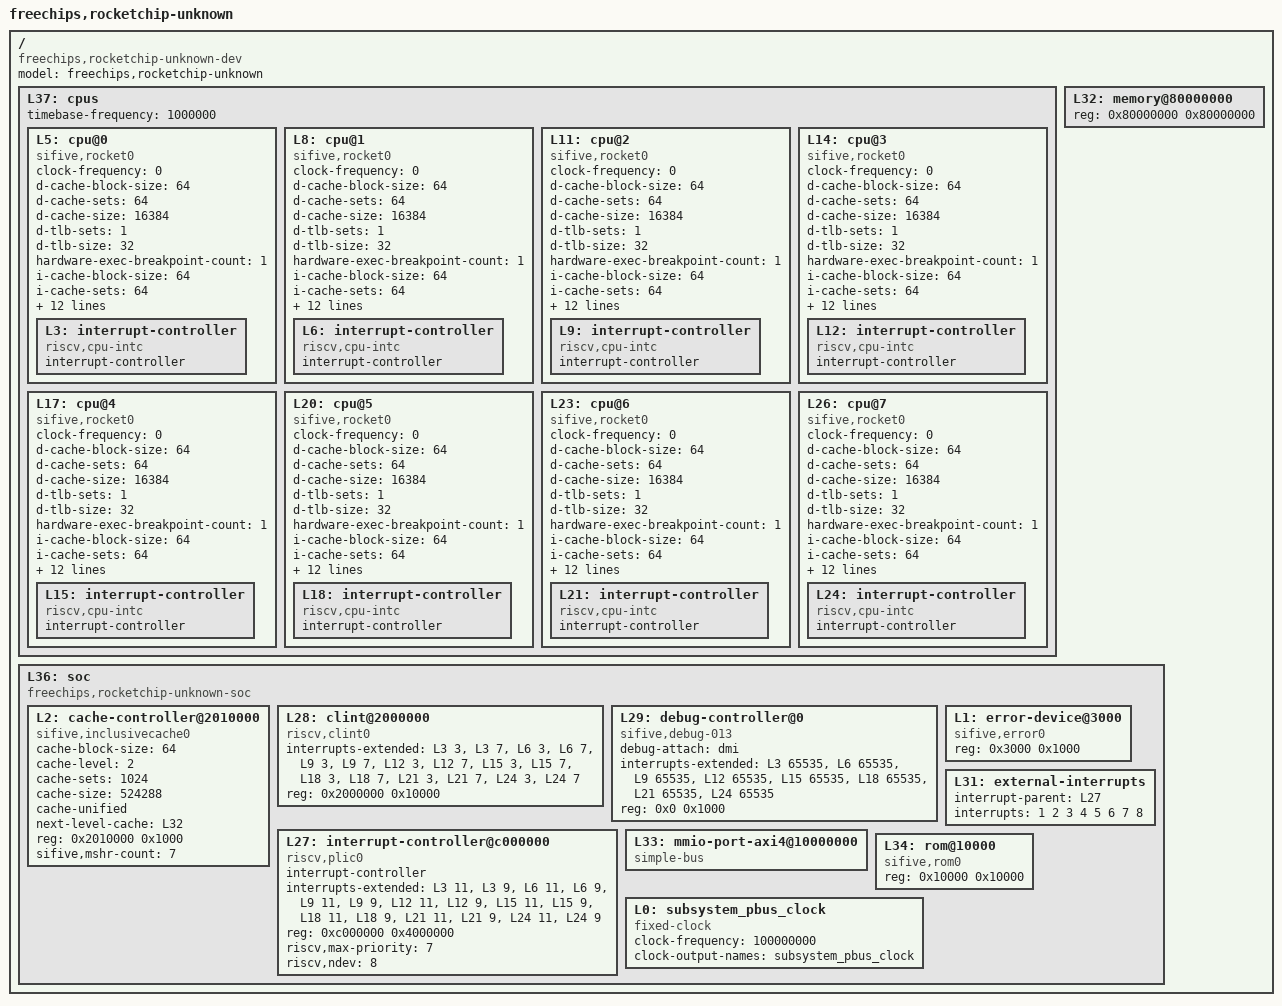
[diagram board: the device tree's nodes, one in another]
/dts-v1/;

/ {
	#address-cells = <1>;
	#size-cells = <1>;
	compatible = "freechips,rocketchip-unknown-dev";
	model = "freechips,rocketchip-unknown";
	L37: cpus {
		#address-cells = <1>;
		#size-cells = <0>;
		timebase-frequency = <1000000>;
		L5: cpu@0 {
			clock-frequency = <0>;
			compatible = "sifive,rocket0", "riscv";
			d-cache-block-size = <64>;
			d-cache-sets = <64>;
			d-cache-size = <16384>;
			d-tlb-sets = <1>;
			d-tlb-size = <32>;
			device_type = "cpu";
			hardware-exec-breakpoint-count = <1>;
			i-cache-block-size = <64>;
			i-cache-sets = <64>;
			i-cache-size = <16384>;
			i-tlb-sets = <1>;
			i-tlb-size = <32>;
			mmu-type = "riscv,sv39,sv39x4";
			next-level-cache = <&L2>;
			reg = <0x0>;
			riscv,isa = "rv64imafdchzicsr_zifencei_zihpm_zba_zbb_zbc_zbkb_zbkc_zbkx_zbs_zknd_zkne_zknh_zksed_zksh_xrocket";
			riscv,pmpgranularity = <4096>;
			riscv,pmpregions = <8>;
			status = "okay";
			timebase-frequency = <1000000>;
			tlb-split;
			L3: interrupt-controller {
				#interrupt-cells = <1>;
				compatible = "riscv,cpu-intc";
				interrupt-controller;
			};
		};
		L8: cpu@1 {
			clock-frequency = <0>;
			compatible = "sifive,rocket0", "riscv";
			d-cache-block-size = <64>;
			d-cache-sets = <64>;
			d-cache-size = <16384>;
			d-tlb-sets = <1>;
			d-tlb-size = <32>;
			device_type = "cpu";
			hardware-exec-breakpoint-count = <1>;
			i-cache-block-size = <64>;
			i-cache-sets = <64>;
			i-cache-size = <16384>;
			i-tlb-sets = <1>;
			i-tlb-size = <32>;
			mmu-type = "riscv,sv39,sv39x4";
			next-level-cache = <&L2>;
			reg = <0x1>;
			riscv,isa = "rv64imafdchzicsr_zifencei_zihpm_zba_zbb_zbc_zbkb_zbkc_zbkx_zbs_zknd_zkne_zknh_zksed_zksh_xrocket";
			riscv,pmpgranularity = <4096>;
			riscv,pmpregions = <8>;
			status = "okay";
			timebase-frequency = <1000000>;
			tlb-split;
			L6: interrupt-controller {
				#interrupt-cells = <1>;
				compatible = "riscv,cpu-intc";
				interrupt-controller;
			};
		};
		L11: cpu@2 {
			clock-frequency = <0>;
			compatible = "sifive,rocket0", "riscv";
			d-cache-block-size = <64>;
			d-cache-sets = <64>;
			d-cache-size = <16384>;
			d-tlb-sets = <1>;
			d-tlb-size = <32>;
			device_type = "cpu";
			hardware-exec-breakpoint-count = <1>;
			i-cache-block-size = <64>;
			i-cache-sets = <64>;
			i-cache-size = <16384>;
			i-tlb-sets = <1>;
			i-tlb-size = <32>;
			mmu-type = "riscv,sv39,sv39x4";
			next-level-cache = <&L2>;
			reg = <0x2>;
			riscv,isa = "rv64imafdchzicsr_zifencei_zihpm_zba_zbb_zbc_zbkb_zbkc_zbkx_zbs_zknd_zkne_zknh_zksed_zksh_xrocket";
			riscv,pmpgranularity = <4096>;
			riscv,pmpregions = <8>;
			status = "okay";
			timebase-frequency = <1000000>;
			tlb-split;
			L9: interrupt-controller {
				#interrupt-cells = <1>;
				compatible = "riscv,cpu-intc";
				interrupt-controller;
			};
		};
		L14: cpu@3 {
			clock-frequency = <0>;
			compatible = "sifive,rocket0", "riscv";
			d-cache-block-size = <64>;
			d-cache-sets = <64>;
			d-cache-size = <16384>;
			d-tlb-sets = <1>;
			d-tlb-size = <32>;
			device_type = "cpu";
			hardware-exec-breakpoint-count = <1>;
			i-cache-block-size = <64>;
			i-cache-sets = <64>;
			i-cache-size = <16384>;
			i-tlb-sets = <1>;
			i-tlb-size = <32>;
			mmu-type = "riscv,sv39,sv39x4";
			next-level-cache = <&L2>;
			reg = <0x3>;
			riscv,isa = "rv64imafdchzicsr_zifencei_zihpm_zba_zbb_zbc_zbkb_zbkc_zbkx_zbs_zknd_zkne_zknh_zksed_zksh_xrocket";
			riscv,pmpgranularity = <4096>;
			riscv,pmpregions = <8>;
			status = "okay";
			timebase-frequency = <1000000>;
			tlb-split;
			L12: interrupt-controller {
				#interrupt-cells = <1>;
				compatible = "riscv,cpu-intc";
				interrupt-controller;
			};
		};
		L17: cpu@4 {
			clock-frequency = <0>;
			compatible = "sifive,rocket0", "riscv";
			d-cache-block-size = <64>;
			d-cache-sets = <64>;
			d-cache-size = <16384>;
			d-tlb-sets = <1>;
			d-tlb-size = <32>;
			device_type = "cpu";
			hardware-exec-breakpoint-count = <1>;
			i-cache-block-size = <64>;
			i-cache-sets = <64>;
			i-cache-size = <16384>;
			i-tlb-sets = <1>;
			i-tlb-size = <32>;
			mmu-type = "riscv,sv39,sv39x4";
			next-level-cache = <&L2>;
			reg = <0x4>;
			riscv,isa = "rv64imafdchzicsr_zifencei_zihpm_zba_zbb_zbc_zbkb_zbkc_zbkx_zbs_zknd_zkne_zknh_zksed_zksh_xrocket";
			riscv,pmpgranularity = <4096>;
			riscv,pmpregions = <8>;
			status = "okay";
			timebase-frequency = <1000000>;
			tlb-split;
			L15: interrupt-controller {
				#interrupt-cells = <1>;
				compatible = "riscv,cpu-intc";
				interrupt-controller;
			};
		};
		L20: cpu@5 {
			clock-frequency = <0>;
			compatible = "sifive,rocket0", "riscv";
			d-cache-block-size = <64>;
			d-cache-sets = <64>;
			d-cache-size = <16384>;
			d-tlb-sets = <1>;
			d-tlb-size = <32>;
			device_type = "cpu";
			hardware-exec-breakpoint-count = <1>;
			i-cache-block-size = <64>;
			i-cache-sets = <64>;
			i-cache-size = <16384>;
			i-tlb-sets = <1>;
			i-tlb-size = <32>;
			mmu-type = "riscv,sv39,sv39x4";
			next-level-cache = <&L2>;
			reg = <0x5>;
			riscv,isa = "rv64imafdchzicsr_zifencei_zihpm_zba_zbb_zbc_zbkb_zbkc_zbkx_zbs_zknd_zkne_zknh_zksed_zksh_xrocket";
			riscv,pmpgranularity = <4096>;
			riscv,pmpregions = <8>;
			status = "okay";
			timebase-frequency = <1000000>;
			tlb-split;
			L18: interrupt-controller {
				#interrupt-cells = <1>;
				compatible = "riscv,cpu-intc";
				interrupt-controller;
			};
		};
		L23: cpu@6 {
			clock-frequency = <0>;
			compatible = "sifive,rocket0", "riscv";
			d-cache-block-size = <64>;
			d-cache-sets = <64>;
			d-cache-size = <16384>;
			d-tlb-sets = <1>;
			d-tlb-size = <32>;
			device_type = "cpu";
			hardware-exec-breakpoint-count = <1>;
			i-cache-block-size = <64>;
			i-cache-sets = <64>;
			i-cache-size = <16384>;
			i-tlb-sets = <1>;
			i-tlb-size = <32>;
			mmu-type = "riscv,sv39,sv39x4";
			next-level-cache = <&L2>;
			reg = <0x6>;
			riscv,isa = "rv64imafdchzicsr_zifencei_zihpm_zba_zbb_zbc_zbkb_zbkc_zbkx_zbs_zknd_zkne_zknh_zksed_zksh_xrocket";
			riscv,pmpgranularity = <4096>;
			riscv,pmpregions = <8>;
			status = "okay";
			timebase-frequency = <1000000>;
			tlb-split;
			L21: interrupt-controller {
				#interrupt-cells = <1>;
				compatible = "riscv,cpu-intc";
				interrupt-controller;
			};
		};
		L26: cpu@7 {
			clock-frequency = <0>;
			compatible = "sifive,rocket0", "riscv";
			d-cache-block-size = <64>;
			d-cache-sets = <64>;
			d-cache-size = <16384>;
			d-tlb-sets = <1>;
			d-tlb-size = <32>;
			device_type = "cpu";
			hardware-exec-breakpoint-count = <1>;
			i-cache-block-size = <64>;
			i-cache-sets = <64>;
			i-cache-size = <16384>;
			i-tlb-sets = <1>;
			i-tlb-size = <32>;
			mmu-type = "riscv,sv39,sv39x4";
			next-level-cache = <&L2>;
			reg = <0x7>;
			riscv,isa = "rv64imafdchzicsr_zifencei_zihpm_zba_zbb_zbc_zbkb_zbkc_zbkx_zbs_zknd_zkne_zknh_zksed_zksh_xrocket";
			riscv,pmpgranularity = <4096>;
			riscv,pmpregions = <8>;
			status = "okay";
			timebase-frequency = <1000000>;
			tlb-split;
			L24: interrupt-controller {
				#interrupt-cells = <1>;
				compatible = "riscv,cpu-intc";
				interrupt-controller;
			};
		};
	};
	L32: memory@80000000 {
		device_type = "memory";
		reg = <0x80000000 0x80000000>;
	};
	L36: soc {
		#address-cells = <1>;
		#size-cells = <1>;
		compatible = "freechips,rocketchip-unknown-soc", "simple-bus";
		ranges;
		L2: cache-controller@2010000 {
			cache-block-size = <64>;
			cache-level = <2>;
			cache-sets = <1024>;
			cache-size = <524288>;
			cache-unified;
			compatible = "sifive,inclusivecache0", "cache";
			next-level-cache = <&L32>;
			reg = <0x2010000 0x1000>;
			reg-names = "control";
			sifive,mshr-count = <7>;
		};
		L28: clint@2000000 {
			compatible = "riscv,clint0";
			interrupts-extended = <&L3 3 &L3 7 &L6 3 &L6 7 &L9 3 &L9 7 &L12 3 &L12 7 &L15 3 &L15 7 &L18 3 &L18 7 &L21 3 &L21 7 &L24 3 &L24 7>;
			reg = <0x2000000 0x10000>;
			reg-names = "control";
		};
		L29: debug-controller@0 {
			compatible = "sifive,debug-013", "riscv,debug-013";
			debug-attach = "dmi";
			interrupts-extended = <&L3 65535 &L6 65535 &L9 65535 &L12 65535 &L15 65535 &L18 65535 &L21 65535 &L24 65535>;
			reg = <0x0 0x1000>;
			reg-names = "control";
		};
		L1: error-device@3000 {
			compatible = "sifive,error0";
			reg = <0x3000 0x1000>;
		};
		L31: external-interrupts {
			interrupt-parent = <&L27>;
			interrupts = <1 2 3 4 5 6 7 8>;
		};
		L27: interrupt-controller@c000000 {
			#interrupt-cells = <1>;
			compatible = "riscv,plic0";
			interrupt-controller;
			interrupts-extended = <&L3 11 &L3 9 &L6 11 &L6 9 &L9 11 &L9 9 &L12 11 &L12 9 &L15 11 &L15 9 &L18 11 &L18 9 &L21 11 &L21 9 &L24 11 &L24 9>;
			reg = <0xc000000 0x4000000>;
			reg-names = "control";
			riscv,max-priority = <7>;
			riscv,ndev = <8>;
		};
		L33: mmio-port-axi4@10000000 {
			#address-cells = <1>;
			#size-cells = <1>;
			compatible = "simple-bus";
			ranges = <0x10000000 0x10000000 0x70000000>;
		};
		L34: rom@10000 {
			compatible = "sifive,rom0";
			reg = <0x10000 0x10000>;
			reg-names = "mem";
		};
		L0: subsystem_pbus_clock {
			#clock-cells = <0>;
			clock-frequency = <100000000>;
			clock-output-names = "subsystem_pbus_clock";
			compatible = "fixed-clock";
		};
	};
};
